# STM32H723VEH6 register map
File version: 1.0
Registers are 32-bit, access not given, reset 0x0 unless marked. A register's access mark holds for its fields unless they carry their own. Offsets are from the block's base; [hi:lo] are bit positions; {n}, {i} and the like mark numbered series.

## DLYBSDMMC2
Base 0x48022800
Same registers: DLYBOCTOSPI1 0x52006000, DLYBSDMMC1 0x52008000, DLYBOCTOSPI2 0x5200B000
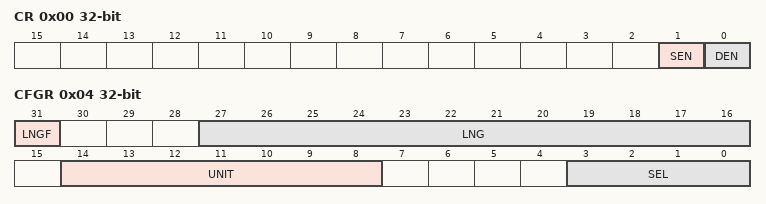
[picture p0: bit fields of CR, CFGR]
0x00 CR
  [1] SEN, [0] DEN
0x04 CFGR
  [31] LNGF, [27:16] LNG, [14:8] UNIT, [3:0] SEL

## RAMECCD2
Base 0x48023000
Same registers: RAMECCD1 0x52009000
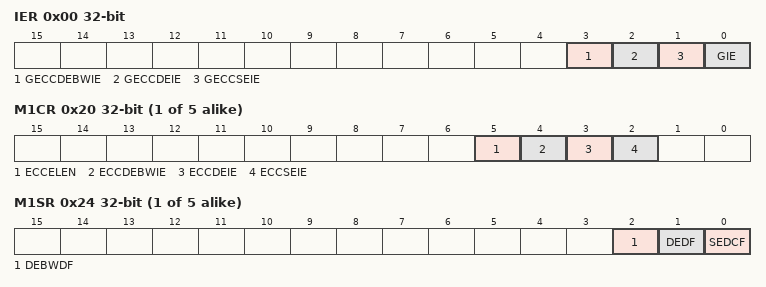
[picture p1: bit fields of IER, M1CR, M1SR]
0x00 IER
  [3] GECCDEBWIE, [2] GECCDEIE, [1] GECCSEIE, [0] GIE
{0x0+0x20*i} M{i}CR (i=1..5)
  [5] ECCELEN, [4] ECCDEBWIE, [3] ECCDEIE, [2] ECCSEIE
{0x4+0x20*i} M{i}SR (i=1..5)
  [2] DEBWDF, [1] DEDF, [0] SEDCF
{0x8+0x20*i} M{i}FAR (i=1..5)
  [31:0] FADD
{0xC+0x20*i} M{i}FDRL (i=1..5)
  [31:0] FDATAL
{0x10+0x20*i} M{i}FDRH (i=1..5)
  [31:0] FDATAH
{0x14+0x20*i} M{i}FECR (i=1..5)
  [31:0] FEC

## FMAC
Base 0x48024000
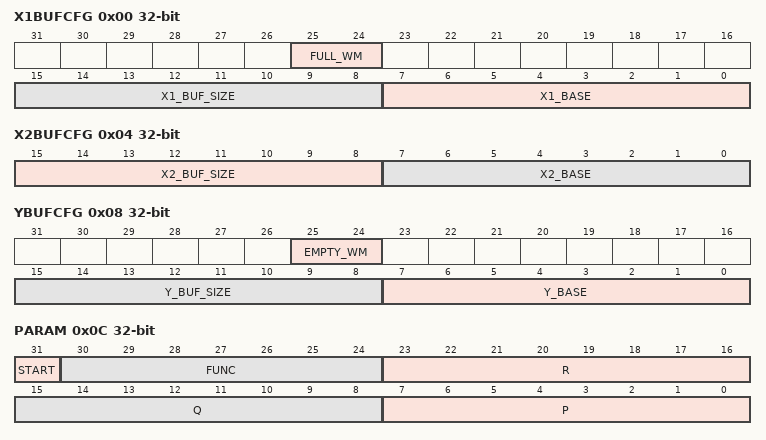
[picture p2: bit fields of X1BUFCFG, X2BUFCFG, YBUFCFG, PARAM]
0x00 X1BUFCFG
  [25:24] FULL_WM, [15:8] X1_BUF_SIZE, [7:0] X1_BASE
0x04 X2BUFCFG
  [15:8] X2_BUF_SIZE, [7:0] X2_BASE
0x08 YBUFCFG
  [25:24] EMPTY_WM, [15:8] Y_BUF_SIZE, [7:0] Y_BASE
0x0C PARAM
  [31] START, [30:24] FUNC, [23:16] R, [15:8] Q, [7:0] P
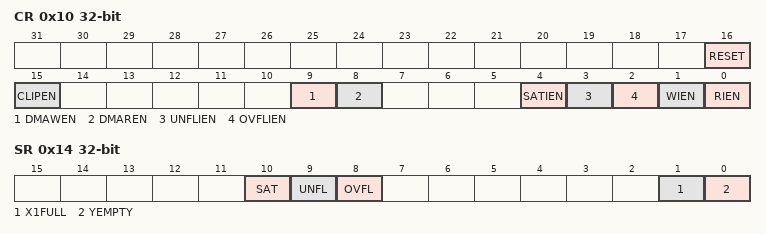
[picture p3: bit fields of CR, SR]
0x10 CR
  [16] RESET, [15] CLIPEN, [9] DMAWEN, [8] DMAREN, [4] SATIEN, [3] UNFLIEN, [2] OVFLIEN, [1] WIEN, [0] RIEN
0x14 SR
  [10] SAT, [9] UNFL, [8] OVFL, [1] X1FULL, [0] YEMPTY
0x18 WDATA
  [15:0] WDATA
0x1C RDATA
  [15:0] RDATA

## CORDIC
Base 0x48024400
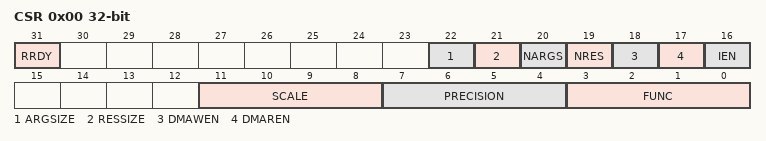
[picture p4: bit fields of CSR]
0x00 CSR
  [31] RRDY, [22] ARGSIZE, [21] RESSIZE, [20] NARGS, [19] NRES, [18] DMAWEN, [17] DMAREN, [16] IEN, [11:8] SCALE, [7:4] PRECISION, [3:0] FUNC
0x04 WDATA
  [31:0] ARG
0x08 RDATA
  [31:0] RES

## LTDC
Base 0x50001000
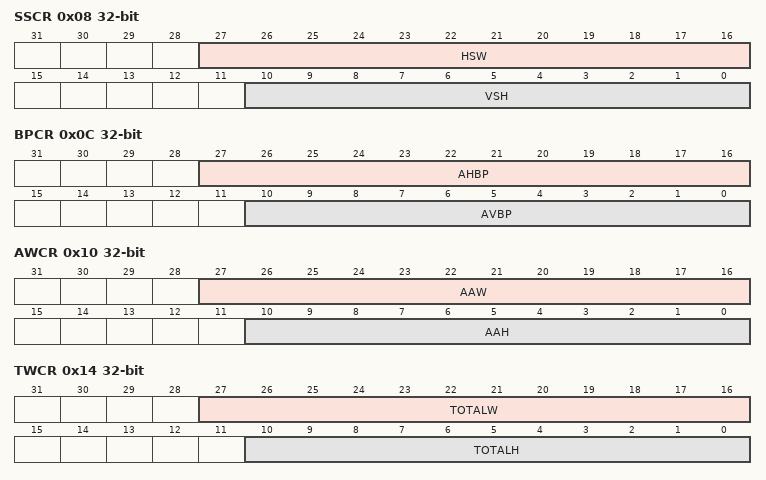
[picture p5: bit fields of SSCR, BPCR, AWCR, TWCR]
0x08 SSCR
  [27:16] HSW, [10:0] VSH
0x0C BPCR
  [27:16] AHBP, [10:0] AVBP
0x10 AWCR
  [27:16] AAW, [10:0] AAH
0x14 TWCR
  [27:16] TOTALW, [10:0] TOTALH
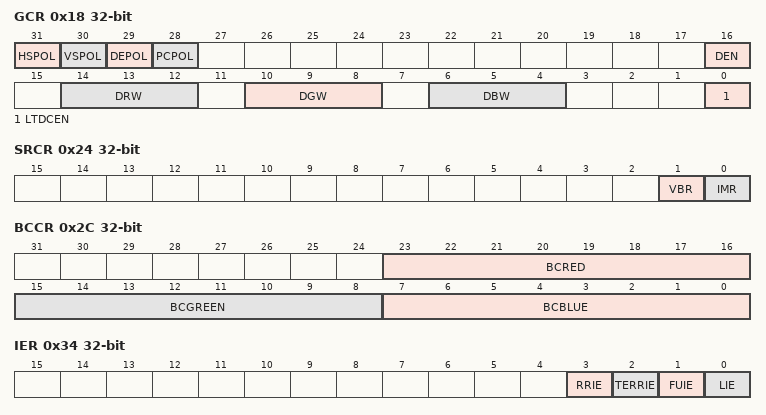
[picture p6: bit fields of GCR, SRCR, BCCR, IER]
0x18 GCR
  [31] HSPOL, [30] VSPOL, [29] DEPOL, [28] PCPOL, [16] DEN, [14:12] DRW, [10:8] DGW, [6:4] DBW, [0] LTDCEN
0x24 SRCR
  [1] VBR, [0] IMR
0x2C BCCR
  [23:16] BCRED, [15:8] BCGREEN, [7:0] BCBLUE
0x34 IER
  [3] RRIE, [2] TERRIE, [1] FUIE, [0] LIE
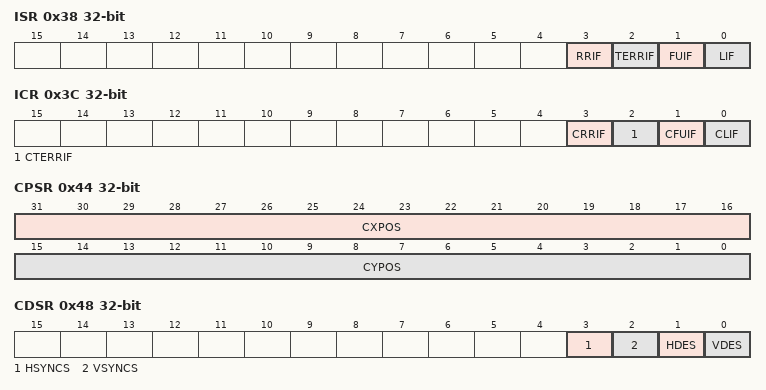
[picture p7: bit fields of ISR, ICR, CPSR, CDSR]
0x38 ISR
  [3] RRIF, [2] TERRIF, [1] FUIF, [0] LIF
0x3C ICR
  [3] CRRIF, [2] CTERRIF, [1] CFUIF, [0] CLIF
0x40 LIPCR
  [10:0] LIPOS
0x44 CPSR
  [31:16] CXPOS, [15:0] CYPOS
0x48 CDSR
  [3] HSYNCS, [2] VSYNCS, [1] HDES, [0] VDES
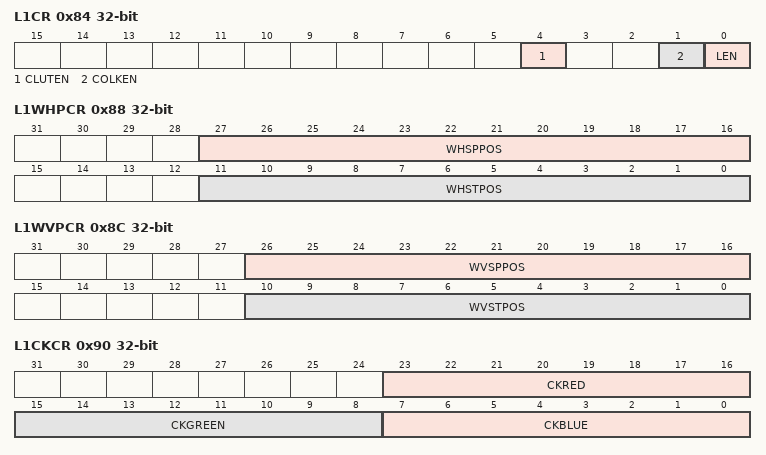
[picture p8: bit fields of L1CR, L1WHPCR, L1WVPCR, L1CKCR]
0x84 L1CR
  [4] CLUTEN, [1] COLKEN, [0] LEN
0x88 L1WHPCR
  [27:16] WHSPPOS, [11:0] WHSTPOS
0x8C L1WVPCR
  [26:16] WVSPPOS, [10:0] WVSTPOS
0x90 L1CKCR
  [23:16] CKRED, [15:8] CKGREEN, [7:0] CKBLUE
0x94 L1PFCR
  [2:0] PF
0x98 L1CACR
  [7:0] CONSTA
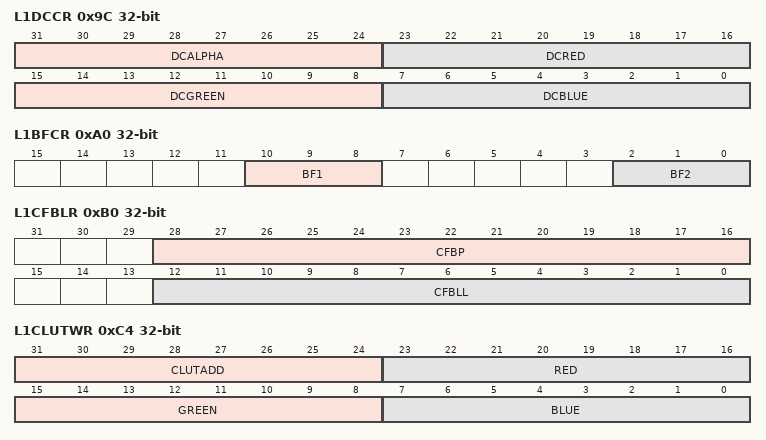
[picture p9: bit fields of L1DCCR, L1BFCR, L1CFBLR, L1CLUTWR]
0x9C L1DCCR
  [31:24] DCALPHA, [23:16] DCRED, [15:8] DCGREEN, [7:0] DCBLUE
0xA0 L1BFCR
  [10:8] BF1, [2:0] BF2
0xAC L1CFBAR
  [31:0] CFBADD
0xB0 L1CFBLR
  [28:16] CFBP, [12:0] CFBLL
0xB4 L1CFBLNR
  [10:0] CFBLNBR
0xC4 L1CLUTWR
  [31:24] CLUTADD, [23:16] RED, [15:8] GREEN, [7:0] BLUE
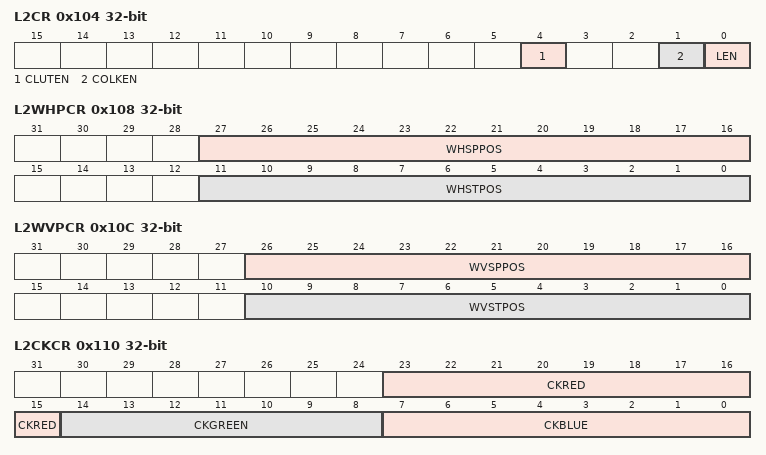
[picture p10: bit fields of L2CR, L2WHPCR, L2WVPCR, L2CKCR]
0x104 L2CR
  [4] CLUTEN, [1] COLKEN, [0] LEN
0x108 L2WHPCR
  [27:16] WHSPPOS, [11:0] WHSTPOS
0x10C L2WVPCR
  [26:16] WVSPPOS, [10:0] WVSTPOS
0x110 L2CKCR
  [23:15] CKRED, [14:8] CKGREEN, [7:0] CKBLUE
0x114 L2PFCR
  [2:0] PF
0x118 L2CACR
  [7:0] CONSTA
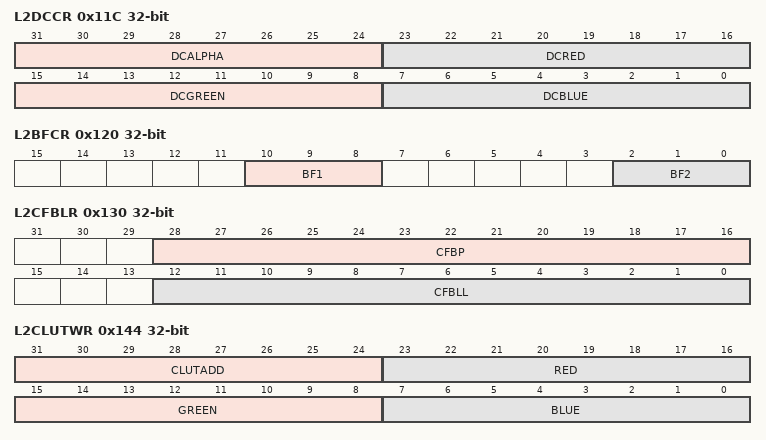
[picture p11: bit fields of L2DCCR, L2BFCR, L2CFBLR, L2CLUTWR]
0x11C L2DCCR
  [31:24] DCALPHA, [23:16] DCRED, [15:8] DCGREEN, [7:0] DCBLUE
0x120 L2BFCR
  [10:8] BF1, [2:0] BF2
0x12C L2CFBAR
  [31:0] CFBADD
0x130 L2CFBLR
  [28:16] CFBP, [12:0] CFBLL
0x134 L2CFBLNR
  [10:0] CFBLNBR
0x144 L2CLUTWR
  [31:24] CLUTADD, [23:16] RED, [15:8] GREEN, [7:0] BLUE

## WWDG
Base 0x50003000
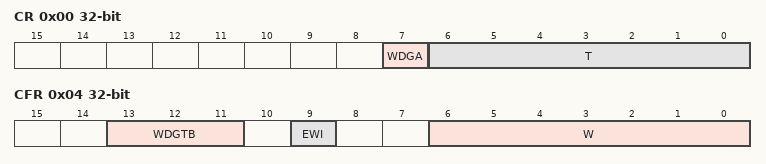
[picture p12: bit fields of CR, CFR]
0x00 CR
  [7] WDGA, [6:0] T
0x04 CFR
  [13:11] WDGTB, [9] EWI, [6:0] W
0x08 SR
  [0] EWIF

## MDMA
Base 0x52000000
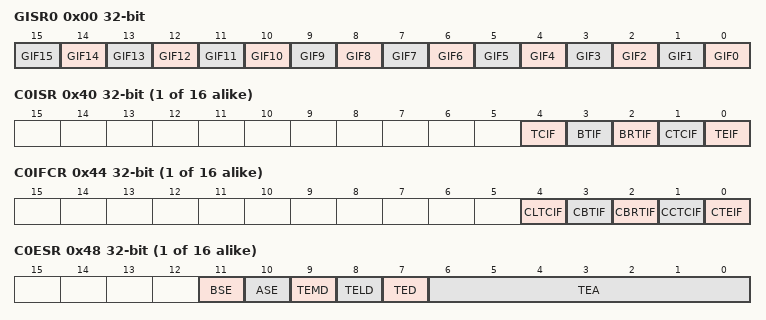
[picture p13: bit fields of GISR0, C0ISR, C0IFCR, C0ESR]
0x00 GISR0
  [n] GIF{n} (n=0..15)
{0x40+0x40*i} C{i}ISR (i=0..15)
  [4] TCIF, [3] BTIF, [2] BRTIF, [1] CTCIF, [0] TEIF
{0x44+0x40*i} C{i}IFCR (i=0..15)
  [4] CLTCIF, [3] CBTIF, [2] CBRTIF, [1] CCTCIF, [0] CTEIF
{0x48+0x40*i} C{i}ESR (i=0..15)
  [11] BSE, [10] ASE, [9] TEMD, [8] TELD, [7] TED, [6:0] TEA
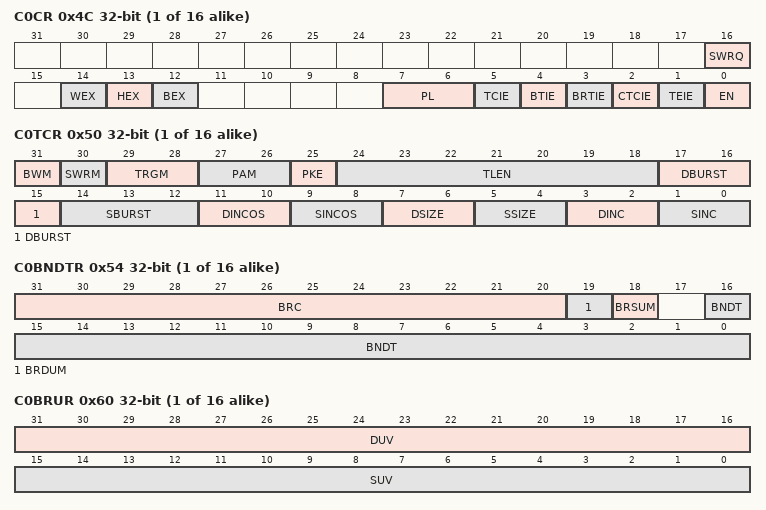
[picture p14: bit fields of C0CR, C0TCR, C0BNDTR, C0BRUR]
{0x4C+0x40*i} C{i}CR (i=0..15)
  [16] SWRQ, [14] WEX, [13] HEX, [12] BEX, [7:6] PL, [5] TCIE, [4] BTIE, [3] BRTIE, [2] CTCIE, [1] TEIE, [0] EN
{0x50+0x40*i} C{i}TCR (i=0..15)
  [31] BWM, [30] SWRM, [29:28] TRGM, [27:26] PAM, [25] PKE, [24:18] TLEN, [17:15] DBURST, [14:12] SBURST, [11:10] DINCOS, [9:8] SINCOS, [7:6] DSIZE, [5:4] SSIZE, [3:2] DINC, [1:0] SINC
{0x54+0x40*i} C{i}BNDTR (i=0..15)
  [31:20] BRC, [19] BRDUM, [18] BRSUM, [16:0] BNDT
{0x58+0x40*i} C{i}SAR (i=0..15)
  [31:0] SAR
{0x5C+0x40*i} C{i}DAR (i=0..15)
  [31:0] DAR
{0x60+0x40*i} C{i}BRUR (i=0..15)
  [31:16] DUV, [15:0] SUV
{0x64+0x40*i} C{i}LAR (i=0..15)
  [31:0] LAR
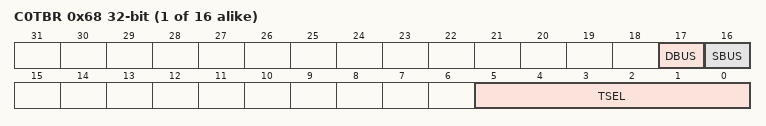
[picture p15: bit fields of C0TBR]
{0x68+0x40*i} C{i}TBR (i=0..15)
  [17] DBUS, [16] SBUS, [5:0] TSEL
{0x70+0x40*i} C{i}MAR (i=0..15)
  [31:0] MAR
{0x74+0x40*i} C{i}MDR (i=0..15)
  [31:0] MDR
